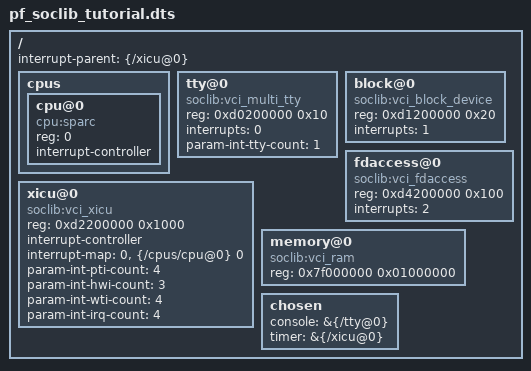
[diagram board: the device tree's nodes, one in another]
/dts-v1/;

/ {
	#address-cells = <1>;
	#size-cells = <1>;
        interrupt-parent = <&{/xicu@0}>;

	cpus {
		#address-cells = <1>;
		#size-cells = <0>;

		cpu@0 {
                        compatible = "cpu:sparc";
			reg = <0>;
                        interrupt-controller;
		};
/*
		cpu@1 {
                        compatible = "cpu:mips";
			reg = <1>;
                        interrupt-controller;
		};

		cpu@2 {
                        compatible = "cpu:mips";
			reg = <2>;
                        interrupt-controller;
		};

		cpu@3 {
                        compatible = "cpu:mips";
			reg = <3>;
                        interrupt-controller;
		};
*/
	};

	tty@0 {
                compatible = "soclib:vci_multi_tty";
		reg = <0xd0200000 0x10>;
		interrupts = <0>;

                param-int-tty-count = <1>;
	};

	block@0 {
	        compatible = "soclib:vci_block_device";
		reg = <0xd1200000 0x20>;
		interrupts = <1>;
	};

	fdaccess@0 {
                compatible = "soclib:vci_fdaccess";
		reg = <0xd4200000 0x100>;
		interrupts = <2>;
	};

	xicu@0 {
	        compatible = "soclib:vci_xicu";
		reg = <0xd2200000 0x1000>;
                interrupt-controller;

                              /*  xicu out   target dev           target in*/
                interrupt-map = < 0          &{/cpus/cpu@0}  0 /*
                                  1          &{/cpus/cpu@1}  0
                                  2          &{/cpus/cpu@2}  0
                                  3          &{/cpus/cpu@3}  0 */ >;

                param-int-pti-count = <4>;
                param-int-hwi-count = <3>;
                param-int-wti-count = <4>;
                param-int-irq-count = <4>;
	};

	memory@0 {
       		compatible = "soclib:vci_ram";
		reg = <0x7f000000 0x01000000>;
	};

	chosen {
		console = &{/tty@0};
                timer = &{/xicu@0};
	};

};

